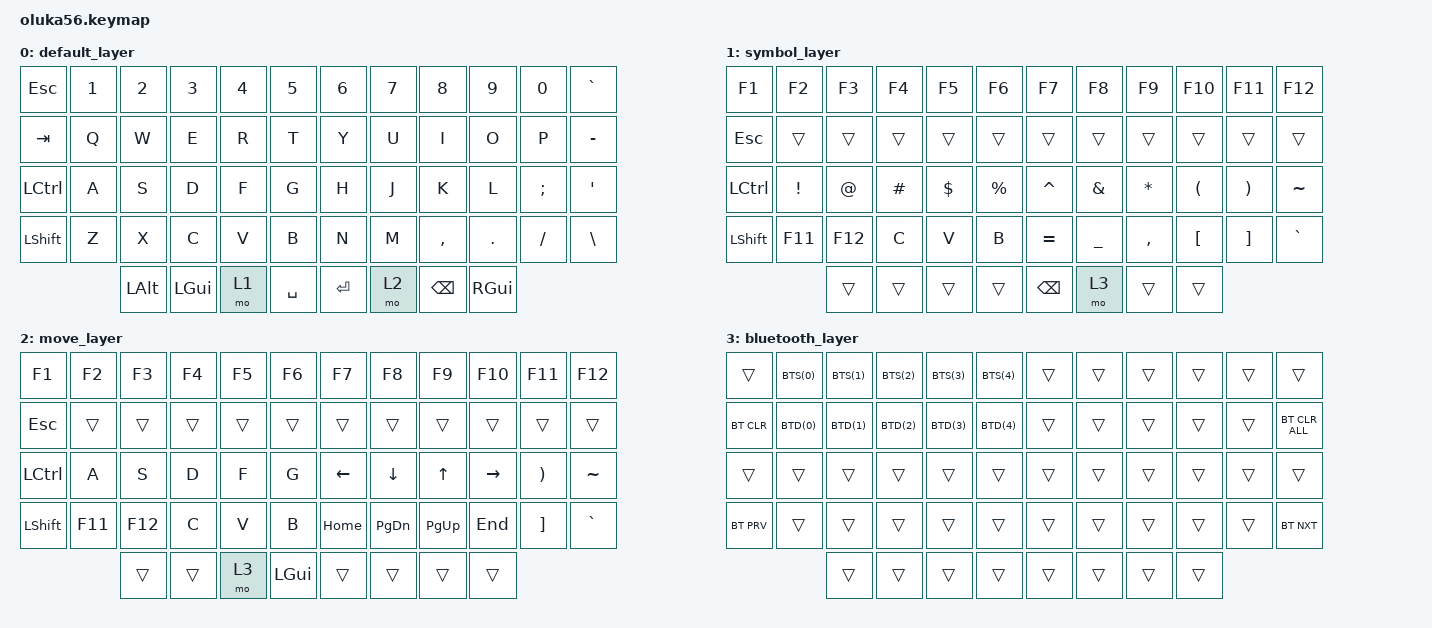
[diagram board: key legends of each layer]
#include <behaviors.dtsi>
#include <dt-bindings/zmk/keys.h>
#include <dt-bindings/zmk/bt.h>

#define BTS(num) &bt BT_SEL num
#define BTD(num) &bt BT_DISC num

/ {
    keymap {
        compatible = "zmk,keymap";

        default_layer { // Layer 0
            bindings = <
&kp ESC   &kp N1  &kp N2   &kp N3   &kp N4   &kp N5      &kp N6  &kp N7  &kp N8    &kp N9  &kp N0    &kp GRAVE
&kp TAB   &kp Q   &kp W    &kp E    &kp R    &kp T       &kp Y   &kp U   &kp I     &kp O   &kp P     &kp MINUS
&kp LCTRL &kp A   &kp S    &kp D    &kp F    &kp G       &kp H   &kp J   &kp K     &kp L   &kp SEMI  &kp SQT
&kp LSHFT &kp Z   &kp X    &kp C    &kp V    &kp B       &kp N   &kp M   &kp COMMA &kp DOT &kp FSLH  &kp BSLH
                  &kp LALT &kp LGUI &mo 1    &kp SPACE   &kp RET &mo 2   &kp BSPC  &kp RGUI
            >;
        };

        symbol_layer { // Layer 1
            bindings = <
&kp F1    &kp F2   &kp F3  &kp F4   &kp F5   &kp F6      &kp F7    &kp F8    &kp F9    &kp F10  &kp F11   &kp F12
&kp ESC   &trans   &trans  &trans   &trans   &trans      &trans    &trans    &trans    &trans   &trans    &trans
&kp LCTRL &kp EXCL &kp AT  &kp HASH &kp DLLR &kp PRCNT   &kp CARET &kp AMPS  &kp STAR  &kp LPAR &kp RPAR  &kp TILDE
&kp LSHFT &kp F11  &kp F12 &kp C    &kp V    &kp B       &kp EQUAL &kp UNDER &kp COMMA &kp LBKT &kp RBKT  &kp GRAVE
                   &trans  &trans   &trans   &trans      &kp BSPC  &mo 3     &trans  &trans
            >;
        };

        move_layer { // Layer 2
            bindings = <
&kp F1    &kp F2   &kp F3  &kp F4   &kp F5   &kp F6      &kp F7    &kp F8    &kp F9    &kp F10  &kp F11   &kp F12
&kp ESC   &trans   &trans  &trans   &trans   &trans      &trans    &trans    &trans    &trans    &trans    &trans
&kp LCTRL &kp A    &kp S   &kp D    &kp F    &kp G       &kp LEFT  &kp DOWN  &kp UP    &kp RIGHT &kp RPAR  &kp TILDE
&kp LSHFT &kp F11  &kp F12 &kp C    &kp V    &kp B       &kp HOME  &kp PG_DN &kp PG_UP &kp END   &kp RBKT  &kp GRAVE
                   &trans  &trans   &mo 3    &kp LGUI    &trans    &trans    &trans  &trans
            >;
        };

        bluetooth_layer { // Layer 3
            bindings = <
&trans     BTS(0)  BTS(1)  BTS(2)  BTS(3)  BTS(4)    &trans  &trans  &trans  &trans  &trans  &trans
&bt BT_CLR BTD(0)  BTD(1)  BTD(2)  BTD(3)  BTD(4)    &trans  &trans  &trans  &trans  &trans  &bt BT_CLR_ALL
&trans     &trans  &trans  &trans  &trans  &trans    &trans  &trans  &trans  &trans  &trans  &trans
&bt BT_PRV &trans  &trans  &trans  &trans  &trans    &trans  &trans  &trans  &trans  &trans  &bt BT_NXT
                   &trans  &trans  &trans  &trans    &trans  &trans  &trans  &trans
            >;
        };
    };
 };
